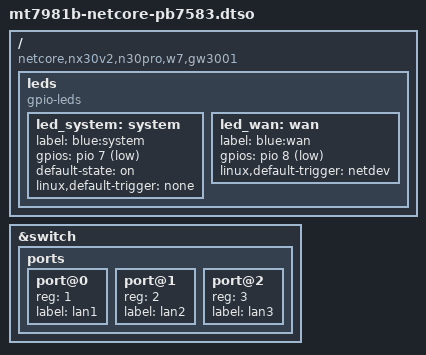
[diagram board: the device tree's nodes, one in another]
/* SPDX-License-Identifier: (GPL-2.0-only OR MIT) */
/dts-v1/;
/plugin/;

#include <dt-bindings/leds/common.h>
#include <dt-bindings/gpio/gpio.h>

/ {

	fragment@0 {
		target-path = "/";
		__overlay__ {
			compatible = "netcore,nx30v2,n30pro,w7,gw3001", "mediatek,mt7981";
		};
	};

	fragment@1 {
		target = <&switch>;
		__overlay__ {
			ports {
				port@0 {
					reg = <1>;
					label = "lan1";
					status = "ok";
				};

				port@1 {
					reg = <2>;
					label = "lan2";
					status = "ok";
				};

				port@2 {
					reg = <3>;
					label = "lan3";
					status = "ok";
				};
			};
		};
	};

	fragment@2 {
		target-path = "/";
		__overlay__ {
			leds{
				compatible = "gpio-leds";

				led_system: system {
					label = "blue:system";
					gpios = <&pio 7 GPIO_ACTIVE_LOW>;
					default-state = "on";
					linux,default-trigger = "none";
				};

				led_wan: wan {
					label = "blue:wan";
					gpios = <&pio 8 GPIO_ACTIVE_LOW>;
					linux,default-trigger = "netdev";
				};
			};
		};
	};

};
